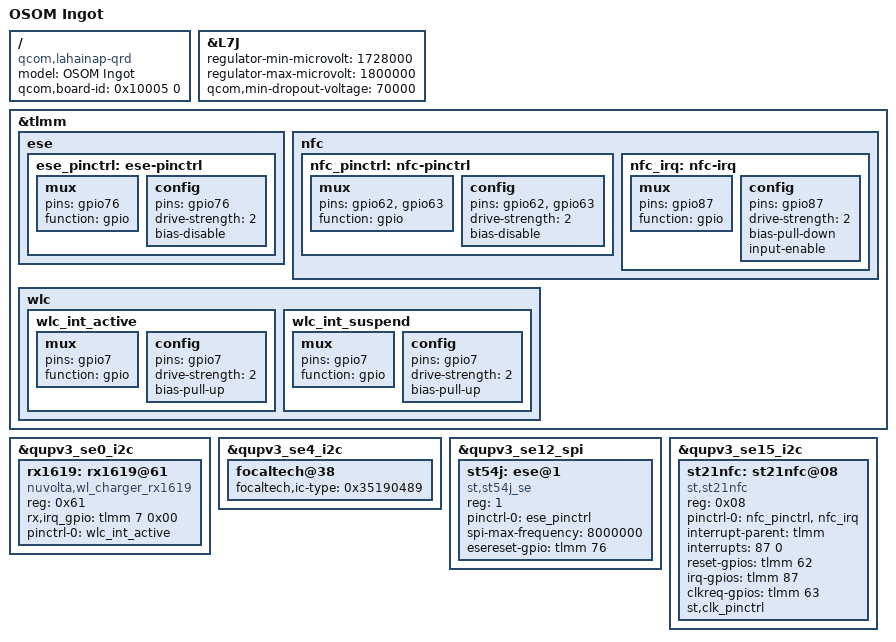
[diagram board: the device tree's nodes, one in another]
/dts-v1/;
/plugin/;

#include "lahainap-qrd.dtsi"
#include "camera/lahaina-camera-sensor-ingot.dtsi"

/ {
	model = "OSOM Ingot";
	compatible = "qcom,lahainap-qrd", "qcom,lahainap", "qcom,qrd";
	qcom,board-id = <0x10005 0>;
};


&L7J {
	regulator-min-microvolt = <1728000>;
	regulator-max-microvolt = <1800000>;
	qcom,min-dropout-voltage = <70000>;
};

&tlmm {
	ese {
		ese_pinctrl: ese-pinctrl {
			mux {
				pins = "gpio76";
				function = "gpio";
			};

			config {
				pins = "gpio76";
				drive-strength = <2>;
				bias-disable;
			};
		};
	};

	nfc {
		nfc_pinctrl: nfc-pinctrl {
			mux {
				pins = "gpio62", "gpio63";
				function = "gpio";
			};

			config {
				pins = "gpio62", "gpio63";
				drive-strength = <2>;
				bias-disable;
			};
		};

		nfc_irq: nfc-irq {
			mux {
				pins = "gpio87";
				function = "gpio";
			};

			config {
				pins = "gpio87";
				drive-strength = <2>;
				bias-pull-down;
				input-enable;
			};
		};
	};

	wlc {
		wlc_int_active: wlc_int_active {
			/* active state */
			mux {
				pins = "gpio7";
				function = "gpio";
			};

			config {
				pins = "gpio7";
				drive-strength = <2>; /* 2 MA */
				bias-pull-up;
			};
		};

		wlc_int_suspend: wlc_int_suspend {
			/* sleep state */
			mux {
				pins = "gpio7";
				function = "gpio";
			};

			config {
				pins = "gpio7";
				drive-strength = <2>; /* 2 MA */
				bias-pull-up;
			};
		};
	};
};

&qupv3_se0_i2c {
	status = "ok";
	rx1619: rx1619@61 {
		compatible = "nuvolta,wl_charger_rx1619";
		reg = <0x61>;
		rx,irq_gpio = <&tlmm 7 0x00>;
		pinctrl-names = "default";
		pinctrl-0 = <&wlc_int_active>;
	};
};

&qupv3_se4_i2c {
	focaltech@38 {
		focaltech,ic-type=<0x35190489>;
	};
};

&qupv3_se12_spi {
	status = "ok";

	st54j: ese@1 {
		compatible = "st,st54j_se";
		reg = <1>;
		pinctrl-names = "default";
		pinctrl-0 = <&ese_pinctrl>;
		spi-max-frequency = <8000000>;
		esereset-gpio = <&tlmm 76 0x00>;
	};
};

&qupv3_se15_i2c {
	/delete-node/ nq@28;

	st21nfc: st21nfc@08 {
		compatible = "st,st21nfc";
		reg = <0x08>;
		pinctrl-names = "default";
		pinctrl-0 = <&nfc_pinctrl>, <&nfc_irq>;
		interrupt-parent = <&tlmm>;
		interrupts = <87  0>;
		reset-gpios = <&tlmm 62 0x00>;
		irq-gpios = <&tlmm 87 0x00>;
		clkreq-gpios = <&tlmm 63 0x00>;
		st,clk_pinctrl;
		status = "ok";
	};
};
